# STM32U5G9xx register map
File version: 1.0
Registers are 32-bit, read-write, reset 0x0 unless marked. A register's access mark holds for its fields unless they carry their own. Offsets are from the block's base; [hi:lo] are bit positions; {n}, {i} and the like mark numbered series; 'fields as' and 'values as' point back to an identical list.

## PWR — Power Control
Base 0x46020800
Same registers: PWR_S 0x56020800
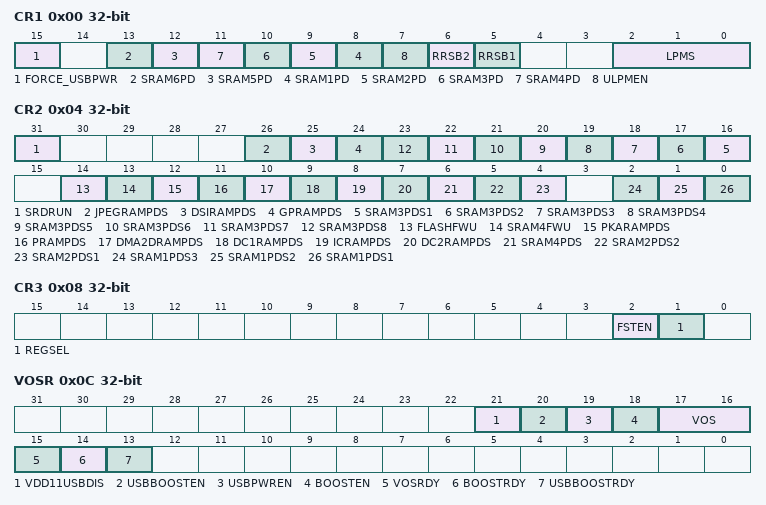
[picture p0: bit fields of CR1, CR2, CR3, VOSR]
0x00 CR1 — Power control register 1
  [15] FORCE_USBPWR
  [13] SRAM6PD — SRAM6 power down
  [12] SRAM5PD — SRAM5 power down
  [n+7] SRAM{n}PD (n=1..4) — SRAM{n} power-down in Run mode
  [7] ULPMEN — BOR ultra-low power mode in Standby/Shutdown
  [6] RRSB2 — SRAM2 page 1 Retention in Standby
  [5] RRSB1 — SRAM2 page 2 Retention in Standby
  [2:0] LPMS — LPMS[2:0] Low-power mode selection field
    {v}=STOP{v}_MODE (v=0..3); 4=STANDBY_MODE; 6=SHUTDOWN_MODE
0x04 CR2 — Power control register 2
  [31] SRDRUN — SmartRun domain in Run mode
    1=RUN_MODE (SmartRun domain AHB3 and APB3 clocks kept enabled in Stop mode (Stop 0, 1, 2)); 0=STOP_MODE (SmartRun domain AHB3 and APB3 clocks disabled by default in Stop mode (Stop 0, 1, 2))
  [26] JPEGRAMPDS — JPEG SRAM power-down in Stop modes (Stop 0, 1)
  [25] DSIRAMPDS — DSI SRAM power-down in Stop modes (Stop 0, 1)
  [24] GPRAMPDS — Graphic peripherals (LTDC, GFXMMU) SRAM power-down in Stop modes (Stop 0, 1, 2, 3)
  [n+15] SRAM3PDS{n} (n=1..8) — SRAM3 page {n} (64 KB) power-down in Stop modes (Stop 0, 1, 2, 3)
  [14] FLASHFWU — Flash memory fast wakeup from Stop modes (Stop 0, 1)
  [13] SRAM4FWU — SRAM4 fast wakeup from Stop modes (Stop 0, 1, 2)
  [12] PKARAMPDS — PKA32 SRAM power-down in Stop modes (Stop 0, 1, 2, 3)
  [11] PRAMPDS — FDCAN and USB peripherals SRAM power-down in Stop modes (Stop 0, 1, 2, 3)
  [10] DMA2DRAMPDS — DMA2D SRAM power-down in Stop modes (Stop 0, 1, 2, 3)
  [9] DC1RAMPDS — DCACHE1 SRAM power-down in Stop modes (Stop 0, 1, 2, 3)
  [8] ICRAMPDS — ICACHE SRAM power-down in Stop modes (Stop 0, 1, 2, 3)
  [7] DC2RAMPDS — DCACHE2 SRAM power-down in Stop modes (Stop 0, 1, 2, 3)
  [6] SRAM4PDS — SRAM4 power-down in Stop modes (Stop 0, 1, 2, 3)
  [5] SRAM2PDS2 — SRAM2 page 2 (56 KB) power-down in Stop modes (Stop 0, 1, 2, 3)
  [4] SRAM2PDS1 — SRAM2 page 1 (8 KB) power-down in Stop modes (Stop 0, 1, 2, 3)
  [2] SRAM1PDS3 — SRAM1 page 3 (64 KB) power-down in Stop modes (Stop 0, 1, 2, 3)
  [1] SRAM1PDS2 — SRAM1 page 2 (64 KB) power-down in Stop modes (Stop 0, 1, 2, 3)
  [0] SRAM1PDS1 — SRAM1 page 1 (64 KB) power-down in Stop modes (Stop 0, 1, 2, 3)
0x08 CR3 — Power control register 3
  [2] FSTEN — Fast soft start
  [1] REGSEL — Regulator selection
    0=LDO_SUPPLY (LDO regulator supply); 1=SMPS_SUPPLY (SMPS regulator supply)
0x0C VOSR — Power voltage scaling register
  [21] VDD11USBDIS — OTG_HS VDD11USB disable
  [20] USBBOOSTEN — USB EPOD booster enable
  [19] USBPWREN — USB Power enable
  [18] BOOSTEN — EPOD booster enable
  [17:16] VOS — VOS[1:0] Voltage scaling range selection field
    3=SCALE1 (Voltage scaling range 1); 2=SCALE2 (Voltage scaling range 2); 1=SCALE3 (Voltage scaling range 3); 0=SCALE4 (Voltage scaling range 4)
  [15] VOSRDY — Ready bit for VCORE voltage scaling output selection
  [14] BOOSTRDY — EPOD booster ready
  [13] USBBOOSTRDY — USB EPOD booster ready
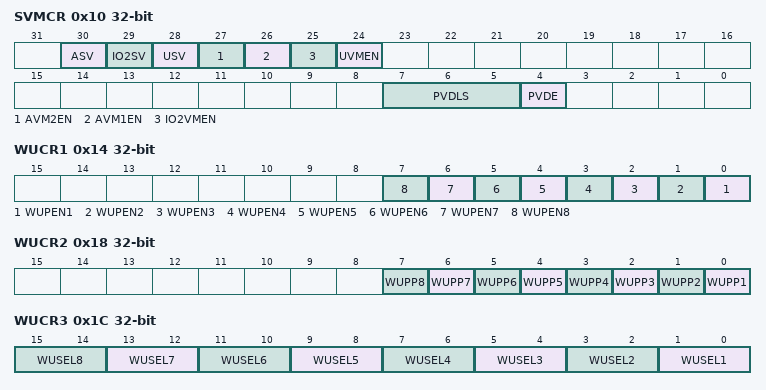
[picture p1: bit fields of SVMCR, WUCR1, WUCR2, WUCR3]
0x10 SVMCR — Power supply voltage monitoring control register
  [30] ASV — VDDA Independent analog supply valid
  [29] IO2SV — VDDIO2 Independent I/Os supply valid
  [28] USV — VDDUSB Independent USB supply valid
  [27] AVM2EN — VDDA Independent analog supply voltage monitor 2 enable
  [26] AVM1EN — VDDA Independent analog supply voltage monitor 1 enable
  [25] IO2VMEN — VDDIO2 Independent I/Os voltage monitor enable
  [24] UVMEN — VDDUSB Independent USB supply voltage monitor enable
  [7:5] PVDLS — PVDLS[2:0] Programmable voltage detector level selection field
    0=PVDLEVEL_0 (Voltage threshold detected by PVD 2.0 V); 1=PVDLEVEL_1 (Voltage threshold detected by PVD 2.2 V); 2=PVDLEVEL_2 (Voltage threshold detected by PVD 2.4 V); 3=PVDLEVEL_3 (Voltage threshold detected by PVD 2.5 V); 4=PVDLEVEL_4 (Voltage threshold detected by PVD 2.6 V); 5=PVDLEVEL_5 (Voltage threshold detected by PVD 2.8 V); 6=PVDLEVEL_6 (Voltage threshold detected by PVD 2.9 V); 7=PVDLEVEL_7
  [4] PVDE — Programmable voltage detector enable
0x14 WUCR1 — Power wakeup control register 1
  [n-1] WUPEN{n} (n=1..8) — Wakeup pin WKUP{n} enable
0x18 WUCR2 — Power wakeup control register 2
  [n-1] WUPP{n} (n=1..8) — Wakeup pin WKUP{n} polarity
0x1C WUCR3 — Power wakeup control register 3
  [2n-1:2n-2] WUSEL{n} (n=1..8) — Wakeup pin WKUP{n} selection field
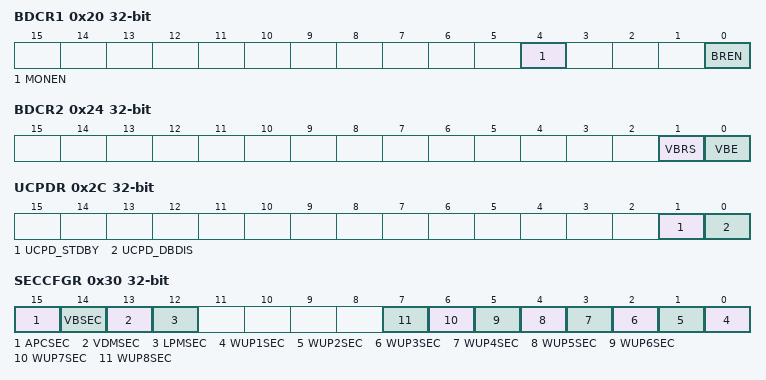
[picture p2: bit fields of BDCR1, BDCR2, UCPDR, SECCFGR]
0x20 BDCR1 — Power backup domain control register 1
  [4] MONEN — Backup Domain voltage and temperature monitoring enable
  [0] BREN — Backup regulator enable
0x24 BDCR2 — Power backup domain control register 2
  [1] VBRS — VBAT charging resistor selection
    0=RESISTOR_5K (Charge the battery through a 5 kO resistor); 1=RESISTOR_1_5K (Charge the battery through a 1.5 kO resistor)
  [0] VBE — VBAT charging enable
0x28 DBPR — Power disable backup domain register
  [0] DBP — Disable backup domain write protection
0x2C UCPDR — Power USB Type-C and Power Delivery register
  [1] UCPD_STDBY — USB Type-C and Power Delivery Standby mode
  [0] UCPD_DBDIS — USB Type-C and Power Delivery Dead Battery disable
0x30 SECCFGR — Power Security configuration register
  [15] APCSEC — Pull-up/pull-down secure protection
  [14] VBSEC — Backup domain secure protection
  [13] VDMSEC — Voltage detection and monitoring secure protection
  [12] LPMSEC — Low-power modes secure protection
  [n-1] WUP{n}SEC (n=1..8) — WUP{n} secure protection
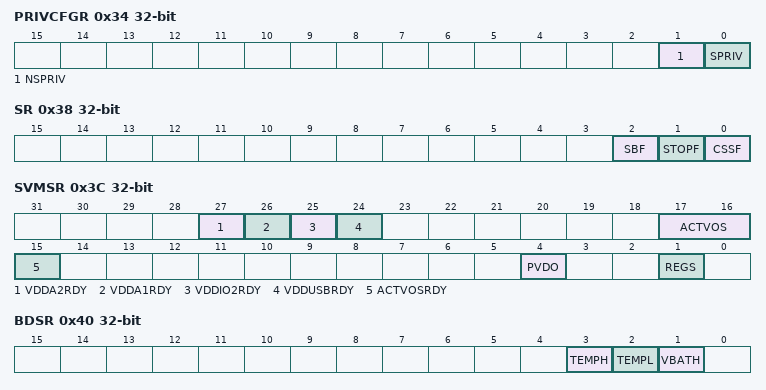
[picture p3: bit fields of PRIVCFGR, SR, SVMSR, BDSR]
0x34 PRIVCFGR — Power privilege control register
  [1] NSPRIV — RCC non-secure functions privilege configuration
  [0] SPRIV — RCC secure functions privilege configuration
0x38 SR — Power status register
  [2] SBF — Standby/Shutdown flag
  [1] STOPF — Stop flag
  [0] CSSF — Clear Stop and Standby/Shutdown flags
0x3C SVMSR — Power supply voltage monitoring status register
  [27] VDDA2RDY — VDDA ready versus 1.8V voltage monitor
  [26] VDDA1RDY — VDDA ready versus 1.6V voltage monitor
  [25] VDDIO2RDY — VDDIO2 ready
  [24] VDDUSBRDY — VDDUSB ready
  [17:16] ACTVOS — Voltage Output Scaling currently applied to VCORE
    values as VOSR.VOS
  [15] ACTVOSRDY — Voltage level ready for currently used VOS
  [4] PVDO — VDD voltage detector output
  [1] REGS — Regulator status
0x40 BDSR — Power backup domain status register
  [3] TEMPH — Temperature level monitoring versus high threshold
  [2] TEMPL — Temperature level monitoring versus low threshold
  [1] VBATH — VBAT level monitoring versus high threshold
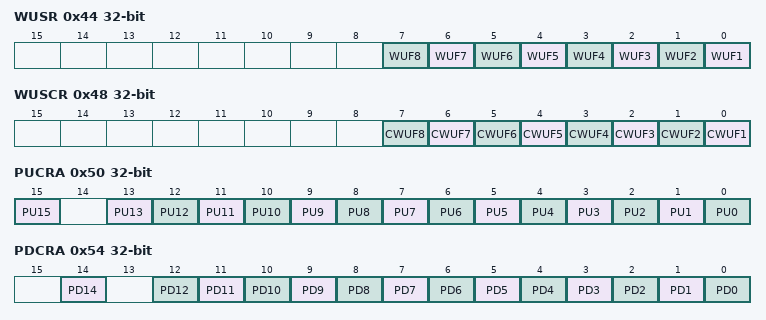
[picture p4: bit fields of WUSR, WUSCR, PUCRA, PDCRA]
0x44 WUSR — Power wakeup status register
  [n-1] WUF{n} (n=1..8) — Wakeup flag {n}
0x48 WUSCR — Power wakeup status clear register
  [n-1] CWUF{n} (n=1..8) — Wakeup clear flag {n}
0x4C APCR — Power apply pull configuration register
  [0] APC — Apply pull-up and pull-down configuration
0x50 PUCRA — Power Port A pull-up control register
  [15] PU15 — Apply pull-up for PA15
  [n] PU{n} (n=0..13) — Apply pull-up for PA{n}
0x54 PDCRA — Power Port A pull-down control register
  [14] PD14 — Apply pull-down for PA14
  [n] PD{n} (n=0..12) — Apply pull-down for PA{n}
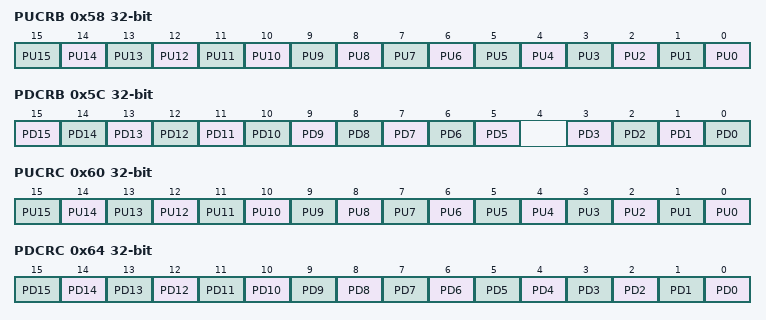
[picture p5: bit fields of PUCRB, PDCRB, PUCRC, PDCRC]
0x58 PUCRB — Power Port B pull-up control register
  [n] PU{n} (n=0..15) — Apply pull-up for PB{n}
0x5C PDCRB — Power Port B pull-down control register
  [n] PD{n} (n=5..15) — Apply pull-down for PB{n}
  [n] PD{n} (n=0..3) — Apply pull-down for PB{n}
0x60 PUCRC — Power Port C pull-up control register
  [n] PU{n} (n=0..15) — Apply pull-up for PC{n}
0x64 PDCRC — Power Port C pull-down control register
  [n] PD{n} (n=0..15) — Apply pull-down for PC{n}
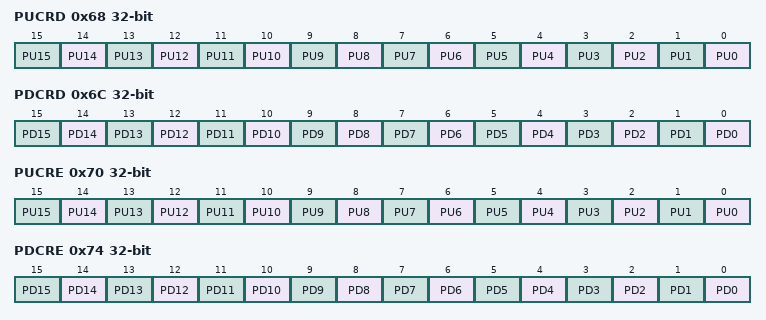
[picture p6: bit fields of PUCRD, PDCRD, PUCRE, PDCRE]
0x68 PUCRD — Power Port D pull-up control register
  [n] PU{n} (n=0..15) — Apply pull-up for PD{n}
0x6C PDCRD — Power Port D pull-down control register
  [n] PD{n} (n=0..15) — Apply pull-down for PD{n}
0x70 PUCRE — Power Port E pull-up control register
  [n] PU{n} (n=0..15) — Apply pull-up for PE{n}
0x74 PDCRE — Power Port E pull-down control register
  [n] PD{n} (n=0..15) — Apply pull-down for PE{n}
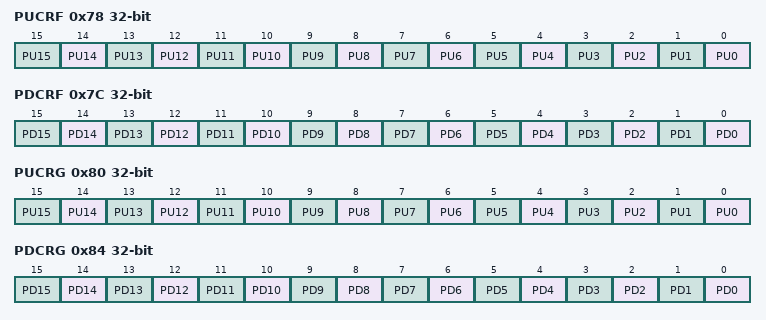
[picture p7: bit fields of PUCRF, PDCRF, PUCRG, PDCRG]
0x78 PUCRF — Power Port F pull-up control register
  [n] PU{n} (n=0..15) — Apply pull-up for PF{n}
0x7C PDCRF — Power Port F pull-down control register
  [n] PD{n} (n=0..15) — Apply pull-down for PF{n}
0x80 PUCRG — Power Port G pull-up control register
  [n] PU{n} (n=0..15) — Apply pull-up for PG{n}
0x84 PDCRG — Power Port G pull-down control register
  [n] PD{n} (n=0..15) — Apply pull-down for PG{n}
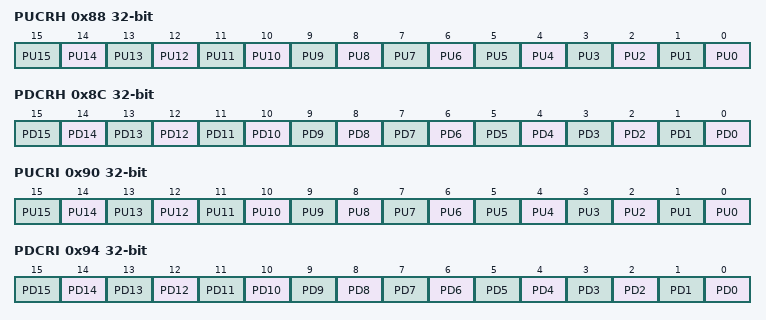
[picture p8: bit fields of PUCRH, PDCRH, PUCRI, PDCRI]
0x88 PUCRH — Power Port H pull-up control register
  [n] PU{n} (n=0..15) — Apply pull-up for PH{n}
0x8C PDCRH — Power Port H pull-down control register
  [n] PD{n} (n=0..15) — Apply pull-down for PH{n}
0x90 PUCRI — Power Port I pull-up control register
  [n] PU{n} (n=0..15) — Apply pull-up for PI{n}
0x94 PDCRI — Power Port I pull-down control register
  [n] PD{n} (n=0..15) — Apply pull-down for PI{n}
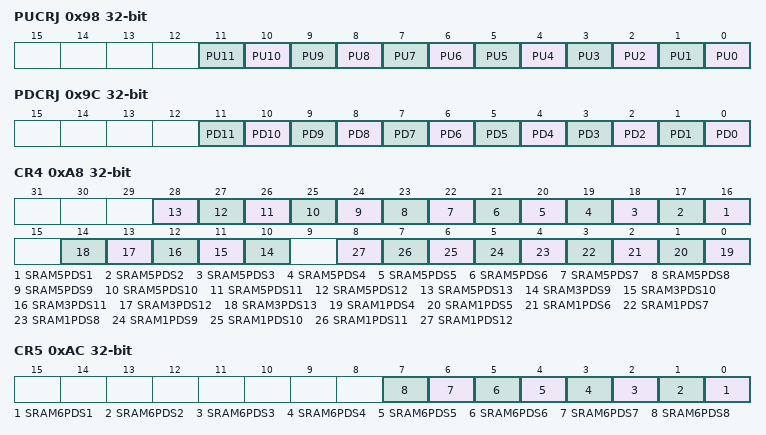
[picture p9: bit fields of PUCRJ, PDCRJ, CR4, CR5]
0x98 PUCRJ — Power Port J pull-up control register
  [n] PU{n} (n=0..11) — Apply pull-up for PJ{n}
0x9C PDCRJ — Power Port J pull-down control register
  [n] PD{n} (n=0..11) — Apply pull-down for PJ{n}
0xA8 CR4 — Power power control register 4
  [n+15] SRAM5PDS{n} (n=1..13) — SRAM5 page {n} (64 KB) power-down in Stop modes (Stop 0, 1, 2, 3)
  [n+1] SRAM3PDS{n} (n=9..13) — SRAM3 page {n} (64 KB) power-down in Stop modes (Stop 0, 1, 2, 3)
  [n-4] SRAM1PDS{n} (n=4..12) — SRAM1 page {n} (64 KB) power-down in Stop modes (Stop 0, 1, 2, 3)
0xAC CR5 — Power power control register 5
  [n-1] SRAM6PDS{n} (n=1..8) — SRAM6 page {n} (64 KB) power-down in Stop modes (Stop 0, 1, 2, 3)
